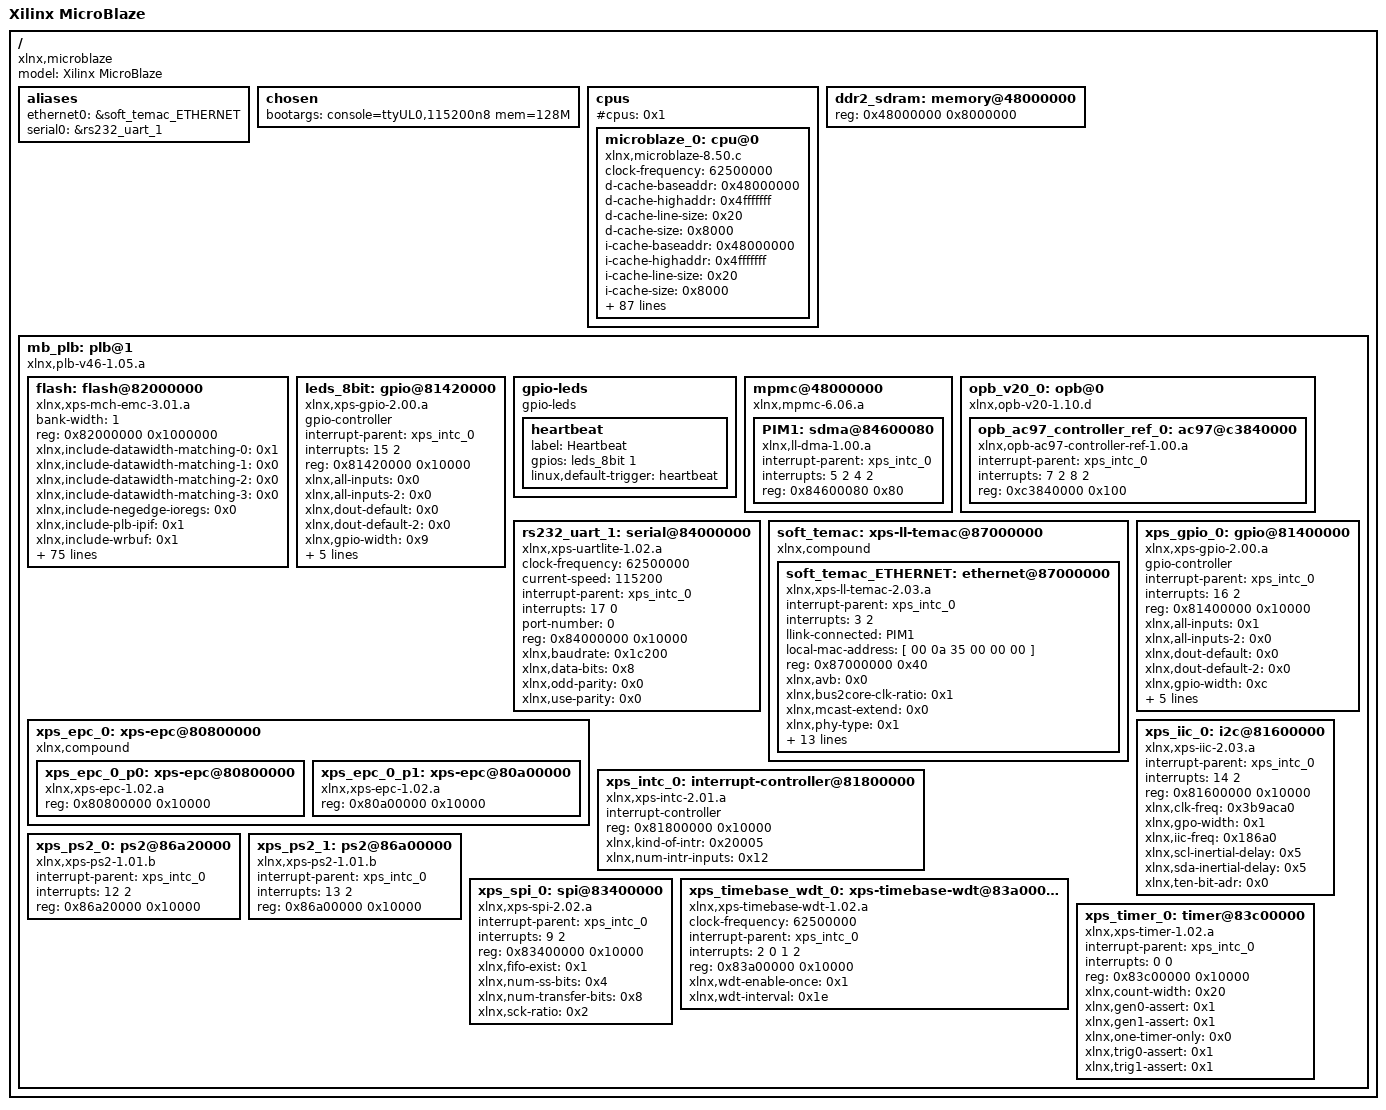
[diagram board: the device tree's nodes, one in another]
/*
 * Device Tree Generator version: 1.1
 *
 * (C) Copyright 2007-2013 Xilinx, Inc.
 * (C) Copyright 2007-2013 Michal Simek
 * (C) Copyright 2007-2012 PetaLogix Qld Pty Ltd
 *
 * Michal SIMEK <monstr@monstr.eu>
 *
 * This program is free software; you can redistribute it and/or
 * modify it under the terms of the GNU General Public License as
 * published by the Free Software Foundation; either version 2 of
 * the License, or (at your option) any later version.
 *
 * This program is distributed in the hope that it will be useful,
 * but WITHOUT ANY WARRANTY; without even the implied warranty of
 * MERCHANTABILITY or FITNESS FOR A PARTICULAR PURPOSE. See the
 * GNU General Public License for more details.
 *
 * You should have received a copy of the GNU General Public License
 * along with this program; if not, write to the Free Software
 * Foundation, Inc., 59 Temple Place, Suite 330, Boston,
 * MA 02111-1307 USA
 *
 * CAUTION: This file is automatically generated by libgen.
 * Version: Xilinx EDK 14.7 EDK_P.20131013
 * Today is: Среда, the 07 of Ноябрь, 2018; 01:04:18
 *
 * XPS project directory: dts
 */

/dts-v1/;
/ {
	#address-cells = <1>;
	#size-cells = <1>;
	compatible = "xlnx,microblaze";
	model = "Xilinx MicroBlaze";
	aliases {
		ethernet0 = &soft_temac_ETHERNET;
		serial0 = &rs232_uart_1;
	} ;
	chosen {
		bootargs = "console=ttyUL0,115200n8 mem=128M";
	} ;
	cpus {
		#address-cells = <1>;
		#cpus = <0x1>;
		#size-cells = <0>;
		microblaze_0: cpu@0 {
			clock-frequency = <62500000>;
			compatible = "xlnx,microblaze-8.50.c";
			d-cache-baseaddr = <0x48000000>;
			d-cache-highaddr = <0x4fffffff>;
			d-cache-line-size = <0x20>;
			d-cache-size = <0x8000>;
			device_type = "cpu";
			i-cache-baseaddr = <0x48000000>;
			i-cache-highaddr = <0x4fffffff>;
			i-cache-line-size = <0x20>;
			i-cache-size = <0x8000>;
			model = "microblaze,8.50.c";
			reg = <0>;
			timebase-frequency = <62500000>;
			xlnx,addr-tag-bits = <0xc>;
			xlnx,allow-dcache-wr = <0x1>;
			xlnx,allow-icache-wr = <0x1>;
			xlnx,area-optimized = <0x0>;
			xlnx,avoid-primitives = <0x0>;
			xlnx,base-vectors = <0x0>;
			xlnx,branch-target-cache-size = <0x0>;
			xlnx,cache-byte-size = <0x8000>;
			xlnx,d-axi = <0x0>;
			xlnx,d-lmb = <0x1>;
			xlnx,d-plb = <0x1>;
			xlnx,data-size = <0x20>;
			xlnx,dcache-addr-tag = <0xc>;
			xlnx,dcache-always-used = <0x1>;
			xlnx,dcache-byte-size = <0x8000>;
			xlnx,dcache-data-width = <0x0>;
			xlnx,dcache-force-tag-lutram = <0x0>;
			xlnx,dcache-interface = <0x1>;
			xlnx,dcache-line-len = <0x8>;
			xlnx,dcache-use-fsl = <0x1>;
			xlnx,dcache-use-writeback = <0x1>;
			xlnx,dcache-victims = <0x8>;
			xlnx,debug-enabled = <0x1>;
			xlnx,div-zero-exception = <0x1>;
			xlnx,dynamic-bus-sizing = <0x1>;
			xlnx,ecc-use-ce-exception = <0x0>;
			xlnx,edge-is-positive = <0x1>;
			xlnx,endianness = <0x0>;
			xlnx,fault-tolerant = <0x0>;
			xlnx,fpu-exception = <0x1>;
			xlnx,freq = <0x3b9aca0>;
			xlnx,fsl-data-size = <0x20>;
			xlnx,fsl-exception = <0x0>;
			xlnx,fsl-links = <0x0>;
			xlnx,i-axi = <0x0>;
			xlnx,i-lmb = <0x1>;
			xlnx,i-plb = <0x1>;
			xlnx,icache-always-used = <0x1>;
			xlnx,icache-data-width = <0x0>;
			xlnx,icache-force-tag-lutram = <0x0>;
			xlnx,icache-interface = <0x0>;
			xlnx,icache-line-len = <0x8>;
			xlnx,icache-streams = <0x1>;
			xlnx,icache-use-fsl = <0x1>;
			xlnx,icache-victims = <0x8>;
			xlnx,ill-opcode-exception = <0x1>;
			xlnx,instance = "microblaze_0";
			xlnx,interconnect = <0x1>;
			xlnx,interrupt-is-edge = <0x0>;
			xlnx,lockstep-slave = <0x0>;
			xlnx,mmu-dtlb-size = <0x4>;
			xlnx,mmu-itlb-size = <0x2>;
			xlnx,mmu-privileged-instr = <0x0>;
			xlnx,mmu-tlb-access = <0x3>;
			xlnx,mmu-zones = <0x2>;
			xlnx,number-of-pc-brk = <0x1>;
			xlnx,number-of-rd-addr-brk = <0x0>;
			xlnx,number-of-wr-addr-brk = <0x0>;
			xlnx,opcode-0x0-illegal = <0x1>;
			xlnx,optimization = <0x0>;
			xlnx,pc-width = <0x20>;
			xlnx,pvr = <0x2>;
			xlnx,pvr-user1 = <0x0>;
			xlnx,pvr-user2 = <0x0>;
			xlnx,reset-msr = <0x0>;
			xlnx,sco = <0x0>;
			xlnx,stream-interconnect = <0x0>;
			xlnx,unaligned-exceptions = <0x1>;
			xlnx,use-barrel = <0x1>;
			xlnx,use-branch-target-cache = <0x0>;
			xlnx,use-dcache = <0x1>;
			xlnx,use-div = <0x1>;
			xlnx,use-ext-brk = <0x1>;
			xlnx,use-ext-nm-brk = <0x1>;
			xlnx,use-extended-fsl-instr = <0x0>;
			xlnx,use-fpu = <0x2>;
			xlnx,use-hw-mul = <0x2>;
			xlnx,use-icache = <0x1>;
			xlnx,use-interrupt = <0x1>;
			xlnx,use-mmu = <0x3>;
			xlnx,use-msr-instr = <0x1>;
			xlnx,use-pcmp-instr = <0x1>;
			xlnx,use-reorder-instr = <0x1>;
			xlnx,use-stack-protection = <0x0>;
		} ;
	} ;
	ddr2_sdram: memory@48000000 {
		device_type = "memory";
		reg = < 0x48000000 0x8000000 >;
	} ;
	mb_plb: plb@1 {
		#address-cells = <1>;
		#size-cells = <1>;
		compatible = "xlnx,plb-v46-1.05.a", "xlnx,plb-v46-1.00.a", "simple-bus";
		ranges ;
		flash: flash@82000000 {
			bank-width = <1>;
			compatible = "xlnx,xps-mch-emc-3.01.a", "cfi-flash";
			reg = < 0x82000000 0x1000000 >;
			xlnx,include-datawidth-matching-0 = <0x1>;
			xlnx,include-datawidth-matching-1 = <0x0>;
			xlnx,include-datawidth-matching-2 = <0x0>;
			xlnx,include-datawidth-matching-3 = <0x0>;
			xlnx,include-negedge-ioregs = <0x0>;
			xlnx,include-plb-ipif = <0x1>;
			xlnx,include-wrbuf = <0x1>;
			xlnx,max-mem-width = <0x8>;
			xlnx,mch-native-dwidth = <0x20>;
			xlnx,mch-splb-awidth = <0x20>;
			xlnx,mch-splb-clk-period-ps = <0x3e80>;
			xlnx,mch0-accessbuf-depth = <0x10>;
			xlnx,mch0-protocol = <0x0>;
			xlnx,mch0-rddatabuf-depth = <0x10>;
			xlnx,mch1-accessbuf-depth = <0x10>;
			xlnx,mch1-protocol = <0x0>;
			xlnx,mch1-rddatabuf-depth = <0x10>;
			xlnx,mch2-accessbuf-depth = <0x10>;
			xlnx,mch2-protocol = <0x0>;
			xlnx,mch2-rddatabuf-depth = <0x10>;
			xlnx,mch3-accessbuf-depth = <0x10>;
			xlnx,mch3-protocol = <0x0>;
			xlnx,mch3-rddatabuf-depth = <0x10>;
			xlnx,mem0-width = <0x8>;
			xlnx,mem1-width = <0x20>;
			xlnx,mem2-width = <0x20>;
			xlnx,mem3-width = <0x20>;
			xlnx,num-banks-mem = <0x1>;
			xlnx,num-channels = <0x0>;
			xlnx,pagemode-flash-0 = <0x0>;
			xlnx,pagemode-flash-1 = <0x0>;
			xlnx,pagemode-flash-2 = <0x0>;
			xlnx,pagemode-flash-3 = <0x0>;
			xlnx,priority-mode = <0x0>;
			xlnx,synch-mem-0 = <0x0>;
			xlnx,synch-mem-1 = <0x0>;
			xlnx,synch-mem-2 = <0x0>;
			xlnx,synch-mem-3 = <0x0>;
			xlnx,synch-pipedelay-0 = <0x2>;
			xlnx,synch-pipedelay-1 = <0x2>;
			xlnx,synch-pipedelay-2 = <0x2>;
			xlnx,synch-pipedelay-3 = <0x2>;
			xlnx,tavdv-ps-mem-0 = <0x11170>;
			xlnx,tavdv-ps-mem-1 = <0x3a98>;
			xlnx,tavdv-ps-mem-2 = <0x3a98>;
			xlnx,tavdv-ps-mem-3 = <0x3a98>;
			xlnx,tcedv-ps-mem-0 = <0x11170>;
			xlnx,tcedv-ps-mem-1 = <0x3a98>;
			xlnx,tcedv-ps-mem-2 = <0x3a98>;
			xlnx,tcedv-ps-mem-3 = <0x3a98>;
			xlnx,thzce-ps-mem-0 = <0x61a8>;
			xlnx,thzce-ps-mem-1 = <0x1b58>;
			xlnx,thzce-ps-mem-2 = <0x1b58>;
			xlnx,thzce-ps-mem-3 = <0x1b58>;
			xlnx,thzoe-ps-mem-0 = <0x61a8>;
			xlnx,thzoe-ps-mem-1 = <0x1b58>;
			xlnx,thzoe-ps-mem-2 = <0x1b58>;
			xlnx,thzoe-ps-mem-3 = <0x1b58>;
			xlnx,tlzwe-ps-mem-0 = <0x1388>;
			xlnx,tlzwe-ps-mem-1 = <0x0>;
			xlnx,tlzwe-ps-mem-2 = <0x0>;
			xlnx,tlzwe-ps-mem-3 = <0x0>;
			xlnx,tpacc-ps-flash-0 = <0x61a8>;
			xlnx,tpacc-ps-flash-1 = <0x61a8>;
			xlnx,tpacc-ps-flash-2 = <0x61a8>;
			xlnx,tpacc-ps-flash-3 = <0x61a8>;
			xlnx,twc-ps-mem-0 = <0x11170>;
			xlnx,twc-ps-mem-1 = <0x3a98>;
			xlnx,twc-ps-mem-2 = <0x3a98>;
			xlnx,twc-ps-mem-3 = <0x3a98>;
			xlnx,twp-ps-mem-0 = <0xafc8>;
			xlnx,twp-ps-mem-1 = <0x2ee0>;
			xlnx,twp-ps-mem-2 = <0x2ee0>;
			xlnx,twp-ps-mem-3 = <0x2ee0>;
			xlnx,xcl0-linesize = <0x4>;
			xlnx,xcl0-writexfer = <0x1>;
			xlnx,xcl1-linesize = <0x4>;
			xlnx,xcl1-writexfer = <0x1>;
			xlnx,xcl2-linesize = <0x4>;
			xlnx,xcl2-writexfer = <0x1>;
			xlnx,xcl3-linesize = <0x4>;
			xlnx,xcl3-writexfer = <0x1>;
		} ;
		leds_8bit: gpio@81420000 {
			#gpio-cells = <2>;
			compatible = "xlnx,xps-gpio-2.00.a", "xlnx,xps-gpio-1.00.a";
			gpio-controller ;
			interrupt-parent = <&xps_intc_0>;
			interrupts = < 15 2 >;
			reg = < 0x81420000 0x10000 >;
			xlnx,all-inputs = <0x0>;
			xlnx,all-inputs-2 = <0x0>;
			xlnx,dout-default = <0x0>;
			xlnx,dout-default-2 = <0x0>;
			xlnx,gpio-width = <0x9>;
			xlnx,gpio2-width = <0x20>;
			xlnx,interrupt-present = <0x1>;
			xlnx,is-dual = <0x0>;
			xlnx,tri-default = <0xffffffff>;
			xlnx,tri-default-2 = <0xffffffff>;
		} ;
        gpio-leds {
                compatible = "gpio-leds";

                heartbeat {
                        label = "Heartbeat";
                        gpios = <&leds_8bit 1 0>;
                        linux,default-trigger = "heartbeat";
                };
        } ;
		mpmc@48000000 {
			#address-cells = <1>;
			#size-cells = <1>;
			compatible = "xlnx,mpmc-6.06.a", "xlnx,mpmc-3.00.a";
			ranges ;
			PIM1: sdma@84600080 {
				compatible = "xlnx,ll-dma-1.00.a";
				interrupt-parent = <&xps_intc_0>;
				interrupts = < 5 2 4 2 >;
				reg = < 0x84600080 0x80 >;
			} ;
		} ;
		opb_v20_0: opb@0 {
			#address-cells = <1>;
			#size-cells = <1>;
			compatible = "xlnx,opb-v20-1.10.d", "simple-bus";
			ranges = < 0xc3840000 0xc3840000 0x100 >;
			opb_ac97_controller_ref_0: ac97@c3840000 {
				compatible = "xlnx,opb-ac97-controller-ref-1.00.a";
				interrupt-parent = <&xps_intc_0>;
				interrupts = < 7 2 8 2 >;
				reg = < 0xc3840000 0x100 >;
			} ;
		} ;
		rs232_uart_1: serial@84000000 {
			clock-frequency = <62500000>;
			compatible = "xlnx,xps-uartlite-1.02.a", "xlnx,xps-uartlite-1.00.a";
			current-speed = <115200>;
			device_type = "serial";
			interrupt-parent = <&xps_intc_0>;
			interrupts = < 17 0 >;
			port-number = <0>;
			reg = < 0x84000000 0x10000 >;
			xlnx,baudrate = <0x1c200>;
			xlnx,data-bits = <0x8>;
			xlnx,odd-parity = <0x0>;
			xlnx,use-parity = <0x0>;
		} ;
		soft_temac: xps-ll-temac@87000000 {
			#address-cells = <1>;
			#size-cells = <1>;
			compatible = "xlnx,compound";
			ranges ;
			soft_temac_ETHERNET: ethernet@87000000 {
				compatible = "xlnx,xps-ll-temac-2.03.a", "xlnx,xps-ll-temac-1.01.b", "xlnx,xps-ll-temac-1.00.a";
				device_type = "network";
				interrupt-parent = <&xps_intc_0>;
				interrupts = < 3 2 >;
				llink-connected = <&PIM1>;
				local-mac-address = [ 00 0a 35 00 00 00 ];
				reg = < 0x87000000 0x40 >;
				xlnx,avb = <0x0>;
				xlnx,bus2core-clk-ratio = <0x1>;
				xlnx,mcast-extend = <0x0>;
				xlnx,phy-type = <0x1>;
				xlnx,phyaddr = <0x1>;
				xlnx,rxcsum = <0x1>;
				xlnx,rxfifo = <0x8000>;
				xlnx,rxvlan-strp = <0x0>;
				xlnx,rxvlan-tag = <0x0>;
				xlnx,rxvlan-tran = <0x0>;
				xlnx,stats = <0x0>;
				xlnx,temac-type = <0x2>;
				xlnx,txcsum = <0x1>;
				xlnx,txfifo = <0x4000>;
				xlnx,txvlan-strp = <0x0>;
				xlnx,txvlan-tag = <0x0>;
				xlnx,txvlan-tran = <0x0>;
			} ;
		} ;
		xps_epc_0: xps-epc@80800000 {
			#address-cells = <1>;
			#size-cells = <1>;
			compatible = "xlnx,compound";
			ranges ;
			xps_epc_0_p0: xps-epc@80800000 {
				compatible = "xlnx,xps-epc-1.02.a";
				reg = < 0x80800000 0x10000 >;
			} ;
			xps_epc_0_p1: xps-epc@80a00000 {
				compatible = "xlnx,xps-epc-1.02.a";
				reg = < 0x80a00000 0x10000 >;
			} ;
		} ;
		xps_gpio_0: gpio@81400000 {
			#gpio-cells = <2>;
			compatible = "xlnx,xps-gpio-2.00.a", "xlnx,xps-gpio-1.00.a";
			gpio-controller ;
			interrupt-parent = <&xps_intc_0>;
			interrupts = < 16 2 >;
			reg = < 0x81400000 0x10000 >;
			xlnx,all-inputs = <0x1>;
			xlnx,all-inputs-2 = <0x0>;
			xlnx,dout-default = <0x0>;
			xlnx,dout-default-2 = <0x0>;
			xlnx,gpio-width = <0xc>;
			xlnx,gpio2-width = <0x20>;
			xlnx,interrupt-present = <0x1>;
			xlnx,is-dual = <0x0>;
			xlnx,tri-default = <0xffffffff>;
			xlnx,tri-default-2 = <0xffffffff>;
		} ;
		xps_iic_0: i2c@81600000 {
			compatible = "xlnx,xps-iic-2.03.a", "xlnx,xps-iic-2.00.a";
			interrupt-parent = <&xps_intc_0>;
			interrupts = < 14 2 >;
			reg = < 0x81600000 0x10000 >;
			xlnx,clk-freq = <0x3b9aca0>;
			xlnx,gpo-width = <0x1>;
			xlnx,iic-freq = <0x186a0>;
			xlnx,scl-inertial-delay = <0x5>;
			xlnx,sda-inertial-delay = <0x5>;
			xlnx,ten-bit-adr = <0x0>;
		} ;
		xps_intc_0: interrupt-controller@81800000 {
			#interrupt-cells = <0x2>;
			compatible = "xlnx,xps-intc-2.01.a", "xlnx,xps-intc-1.00.a";
			interrupt-controller ;
			reg = < 0x81800000 0x10000 >;
			xlnx,kind-of-intr = <0x20005>;
			xlnx,num-intr-inputs = <0x12>;
		} ;
		xps_ps2_0: ps2@86a20000 {
			compatible = "xlnx,xps-ps2-1.01.b", "xlnx,xps-ps2-1.00.a";
			interrupt-parent = <&xps_intc_0>;
			interrupts = < 12 2 >;
			reg = < 0x86a20000 0x10000 >;
		} ;
		xps_ps2_1: ps2@86a00000 {
			compatible = "xlnx,xps-ps2-1.01.b", "xlnx,xps-ps2-1.00.a";
			interrupt-parent = <&xps_intc_0>;
			interrupts = < 13 2 >;
			reg = < 0x86a00000 0x10000 >;
		} ;
		xps_spi_0: spi@83400000 {
			compatible = "xlnx,xps-spi-2.02.a", "xlnx,xps-spi-2.00.a";
			interrupt-parent = <&xps_intc_0>;
			interrupts = < 9 2 >;
			reg = < 0x83400000 0x10000 >;
			xlnx,fifo-exist = <0x1>;
			xlnx,num-ss-bits = <0x4>;
			xlnx,num-transfer-bits = <0x8>;
			xlnx,sck-ratio = <0x2>;
		} ;
		xps_timebase_wdt_0: xps-timebase-wdt@83a00000 {
			clock-frequency = <62500000>;
			compatible = "xlnx,xps-timebase-wdt-1.02.a", "xlnx,xps-timebase-wdt-1.01.a", "xlnx,xps-timebase-wdt-1.00.a";
			interrupt-parent = <&xps_intc_0>;
			interrupts = < 2 0 1 2 >;
			reg = < 0x83a00000 0x10000 >;
			xlnx,wdt-enable-once = <0x1>;
			xlnx,wdt-interval = <0x1e>;
		} ;
		xps_timer_0: timer@83c00000 {
			compatible = "xlnx,xps-timer-1.02.a", "xlnx,xps-timer-1.00.a";
			interrupt-parent = <&xps_intc_0>;
			interrupts = < 0 0 >;
			reg = < 0x83c00000 0x10000 >;
			xlnx,count-width = <0x20>;
			xlnx,gen0-assert = <0x1>;
			xlnx,gen1-assert = <0x1>;
			xlnx,one-timer-only = <0x0>;
			xlnx,trig0-assert = <0x1>;
			xlnx,trig1-assert = <0x1>;
		} ;
	} ;
} ;
